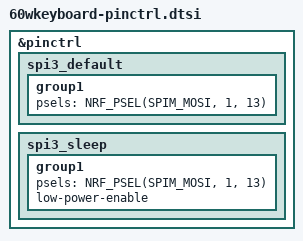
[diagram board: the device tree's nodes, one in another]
&pinctrl {
    spi3_default: spi3_default {
        group1 {
            // Mapping SPIM_MOSI to Port 1, Pin 13
            psels = <NRF_PSEL(SPIM_MOSI, 1, 13)>;
        };
    };

    spi3_sleep: spi3_sleep {
        group1 {
            psels = <NRF_PSEL(SPIM_MOSI, 1, 13)>;
            low-power-enable;
        };
    };
};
